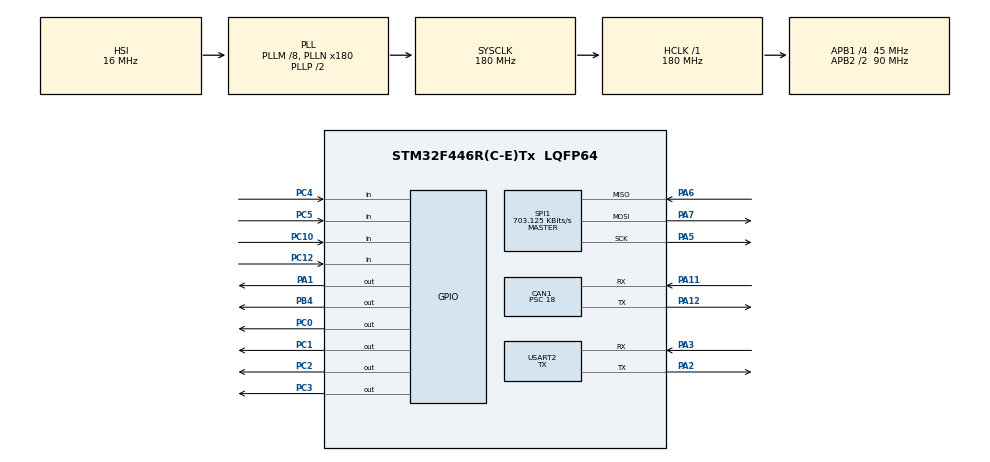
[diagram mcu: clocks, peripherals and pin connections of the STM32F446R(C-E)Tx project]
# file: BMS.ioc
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CAN1.BS1=CAN_BS1_3TQ
CAN1.CalculateBaudRate=500000
CAN1.CalculateTimeBit=2000
CAN1.CalculateTimeQuantum=400.0
CAN1.Prescaler=18
FREERTOS.Mutexes01=FEB_SM_Lock,Dynamic,NULL;FEB_LTC6811_Lock,Dynamic,NULL;FEB_UART_Lock,Dynamic,NULL
FREERTOS.Tasks01=Task1_VT,24,512,Start_Task1_VT,Default,NULL,Dynamic,NULL,NULL;Task2_State,32,256,Start_Task2_State,Default,NULL,Dynamic,NULL,NULL;Task3_Charge,40,256,Start_Task3_Charge,Default,NULL,Dynamic,NULL,NULL;Task4_Balance,33,512,Start_Task4_Balance,Default,NULL,Dynamic,NULL,NULL;Task5_IVT,25,512,Start_Task5_IVT,Default,NULL,Dynamic,NULL,NULL;Task6_CAN,16,128,Start_Task6_CAN,Default,NULL,Dynamic,NULL,NULL
FREERTOS.configUSE_NEWLIB_REENTRANT=1
Mcu.Family=STM32F4
Mcu.Name=STM32F446R(C-E)Tx
Mcu.Package=LQFP64
NVIC.CAN1_RX0_IRQn=true\:5\:0\:false\:false\:true\:true\:true\:true\:true
NVIC.PriorityGroup=NVIC_PRIORITYGROUP_4
NVIC.USART2_IRQn=true\:5\:0\:false\:false\:true\:true\:true\:true\:true
PA1.Signal=GPIO_Output
PA11.Mode=CAN_Activate
PA11.Signal=CAN1_RX
PA12.Mode=CAN_Activate
PA12.Signal=CAN1_TX
PA2.Mode=Asynchronous
PA2.Signal=USART2_TX
PA3.Mode=Asynchronous
PA3.Signal=USART2_RX
PA5.Mode=Full_Duplex_Master
PA5.Signal=SPI1_SCK
PA6.Mode=Full_Duplex_Master
PA6.Signal=SPI1_MISO
PA7.Mode=Full_Duplex_Master
PA7.Signal=SPI1_MOSI
PB4.Signal=GPIO_Output
PC0.Signal=GPIO_Output
PC1.Signal=GPIO_Output
PC10.Signal=GPIO_Input
PC12.Signal=GPIO_Input
PC2.Signal=GPIO_Output
PC3.Signal=GPIO_Output
PC4.Signal=GPIO_Input
PC5.Signal=GPIO_Input
ProjectManager.HeapSize=0x200
ProjectManager.StackSize=0x400
ProjectManager.TargetToolchain=STM32CubeIDE
RCC.AHBFreq_Value=180000000
RCC.APB1CLKDivider=RCC_HCLK_DIV4
RCC.APB1Freq_Value=45000000
RCC.APB1TimFreq_Value=90000000
RCC.APB2CLKDivider=RCC_HCLK_DIV2
RCC.APB2Freq_Value=90000000
RCC.APB2TimFreq_Value=180000000
RCC.CortexFreq_Value=180000000
RCC.HCLKFreq_Value=180000000
RCC.PLLM=8
RCC.PLLN=180
RCC.SYSCLKFreq_VALUE=180000000
RCC.SYSCLKSource=RCC_SYSCLKSOURCE_PLLCLK
RCC.USBFreq_Value=180000000
RCC.VCOOutputFreq_Value=360000000
SPI1.BaudRatePrescaler=SPI_BAUDRATEPRESCALER_128
SPI1.CalculateBaudRate=703.125 KBits/s
SPI1.Direction=SPI_DIRECTION_2LINES
SPI1.Mode=SPI_MODE_MASTER
SPI1.VirtualType=VM_MASTER
TIM4.Prescaler=63
USART2.Mode=MODE_TX
USART2.Parity=PARITY_EVEN
USART2.VirtualMode=VM_ASYNC
VP_FREERTOS_VS_CMSIS_V2.Mode=CMSIS_V2
VP_TIM4_VS_ClockSourceINT.Mode=Internal
board=custom

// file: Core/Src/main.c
/* USER CODE BEGIN Header */
/**
  ******************************************************************************
  * @file           : main.c
  * @brief          : Main program body
  ******************************************************************************
  * @attention
  *
  * Copyright (c) 2023 STMicroelectronics.
  * All rights reserved.
  *
  * This software is licensed under terms that can be found in the LICENSE file
  * in the root directory of this software component.
  * If no LICENSE file comes with this software, it is provided AS-IS.
  *
  ******************************************************************************
  */
/* USER CODE END Header */
#include "main.h"
#include "cmsis_os.h"

CAN_HandleTypeDef hcan1;

SPI_HandleTypeDef hspi1;

TIM_HandleTypeDef htim4;

UART_HandleTypeDef huart2;

/* Definitions for Task1_VT */
osThreadId_t Task1_VTHandle;
const osThreadAttr_t Task1_VT_attributes = {
  .name = "Task1_VT",
  .stack_size = 512 * 4,
  .priority = (osPriority_t) osPriorityNormal,
};
/* Definitions for Task2_State */
osThreadId_t Task2_StateHandle;
const osThreadAttr_t Task2_State_attributes = {
  .name = "Task2_State",
  .stack_size = 256 * 4,
  .priority = (osPriority_t) osPriorityAboveNormal,
};
/* Definitions for Task3_Charge */
osThreadId_t Task3_ChargeHandle;
const osThreadAttr_t Task3_Charge_attributes = {
  .name = "Task3_Charge",
  .stack_size = 256 * 4,
  .priority = (osPriority_t) osPriorityHigh,
};
/* Definitions for Task4_Balance */
osThreadId_t Task4_BalanceHandle;
const osThreadAttr_t Task4_Balance_attributes = {
  .name = "Task4_Balance",
  .stack_size = 512 * 4,
  .priority = (osPriority_t) osPriorityAboveNormal1,
};
/* Definitions for Task5_IVT */
osThreadId_t Task5_IVTHandle;
const osThreadAttr_t Task5_IVT_attributes = {
  .name = "Task5_IVT",
  .stack_size = 512 * 4,
  .priority = (osPriority_t) osPriorityNormal1,
};
/* Definitions for Task6_CAN */
osThreadId_t Task6_CANHandle;
const osThreadAttr_t Task6_CAN_attributes = {
  .name = "Task6_CAN",
  .stack_size = 128 * 4,
  .priority = (osPriority_t) osPriorityBelowNormal,
};
/* Definitions for FEB_SM_Lock */
osMutexId_t FEB_SM_LockHandle;
const osMutexAttr_t FEB_SM_Lock_attributes = {
  .name = "FEB_SM_Lock"
};
/* Definitions for FEB_LTC6811_Lock */
osMutexId_t FEB_LTC6811_LockHandle;
const osMutexAttr_t FEB_LTC6811_Lock_attributes = {
  .name = "FEB_LTC6811_Lock"
};
/* Definitions for FEB_UART_Lock */
osMutexId_t FEB_UART_LockHandle;
const osMutexAttr_t FEB_UART_Lock_attributes = {
  .name = "FEB_UART_Lock"
};

void SystemClock_Config(void);
static void MX_GPIO_Init(void);
static void MX_USART2_UART_Init(void);
static void MX_CAN1_Init(void);
static void MX_TIM4_Init(void);
static void MX_SPI1_Init(void);
void Start_Task1_VT(void *argument);
void Start_Task2_State(void *argument);
void Start_Task3_Charge(void *argument);
void Start_Task4_Balance(void *argument);
void Start_Task5_IVT(void *argument);
void Start_Task6_CAN(void *argument);

int main(void)
{

  /* MCU Configuration--------------------------------------------------------*/

  /* Reset of all peripherals, Initializes the Flash interface and the Systick. */
  HAL_Init();

  /* Configure the system clock */
  SystemClock_Config();

  /* Initialize all configured peripherals */
  MX_GPIO_Init();
  MX_USART2_UART_Init();
  MX_CAN1_Init();
  MX_TIM4_Init();
  MX_SPI1_Init();
  /* USER CODE BEGIN 2 */

  FEB_Main_Setup();

  /* USER CODE END 2 */

  /* Init scheduler */
  osKernelInitialize();
  /* Create the mutex(es) */
  /* creation of FEB_SM_Lock */
  FEB_SM_LockHandle = osMutexNew(&FEB_SM_Lock_attributes);

  /* creation of FEB_LTC6811_Lock */
  FEB_LTC6811_LockHandle = osMutexNew(&FEB_LTC6811_Lock_attributes);

  /* creation of FEB_UART_Lock */
  FEB_UART_LockHandle = osMutexNew(&FEB_UART_Lock_attributes);

  /* Create the thread(s) */
  /* creation of Task1_VT */
  Task1_VTHandle = osThreadNew(Start_Task1_VT, NULL, &Task1_VT_attributes);

  /* creation of Task2_State */
  Task2_StateHandle = osThreadNew(Start_Task2_State, NULL, &Task2_State_attributes);

  /* creation of Task3_Charge */
  Task3_ChargeHandle = osThreadNew(Start_Task3_Charge, NULL, &Task3_Charge_attributes);

  /* creation of Task4_Balance */
  Task4_BalanceHandle = osThreadNew(Start_Task4_Balance, NULL, &Task4_Balance_attributes);

  /* creation of Task5_IVT */
  Task5_IVTHandle = osThreadNew(Start_Task5_IVT, NULL, &Task5_IVT_attributes);

  /* creation of Task6_CAN */
  Task6_CANHandle = osThreadNew(Start_Task6_CAN, NULL, &Task6_CAN_attributes);

  /* Start scheduler */
  osKernelStart();

  /* We should never get here as control is now taken by the scheduler */

  /* Infinite loop */
  while (1)
  {

  }
}

void SystemClock_Config(void)
{
  RCC_OscInitTypeDef RCC_OscInitStruct = {0};
  RCC_ClkInitTypeDef RCC_ClkInitStruct = {0};

  /** Configure the main internal regulator output voltage
  */
  __HAL_RCC_PWR_CLK_ENABLE();
  __HAL_PWR_VOLTAGESCALING_CONFIG(PWR_REGULATOR_VOLTAGE_SCALE1);

  /** Initializes the RCC Oscillators according to the specified parameters
  * in the RCC_OscInitTypeDef structure.
  */
  RCC_OscInitStruct.OscillatorType = RCC_OSCILLATORTYPE_HSI;
  RCC_OscInitStruct.HSIState = RCC_HSI_ON;
  RCC_OscInitStruct.HSICalibrationValue = RCC_HSICALIBRATION_DEFAULT;
  RCC_OscInitStruct.PLL.PLLState = RCC_PLL_ON;
  RCC_OscInitStruct.PLL.PLLSource = RCC_PLLSOURCE_HSI;
  RCC_OscInitStruct.PLL.PLLM = 8;
  RCC_OscInitStruct.PLL.PLLN = 180;
  RCC_OscInitStruct.PLL.PLLP = RCC_PLLP_DIV2;
  RCC_OscInitStruct.PLL.PLLQ = 2;
  RCC_OscInitStruct.PLL.PLLR = 2;
  if (HAL_RCC_OscConfig(&RCC_OscInitStruct) != HAL_OK)
  {
    Error_Handler();
  }

  /** Activate the Over-Drive mode
  */
  if (HAL_PWREx_EnableOverDrive() != HAL_OK)
  {
    Error_Handler();
  }

  /** Initializes the CPU, AHB and APB buses clocks
  */
  RCC_ClkInitStruct.ClockType = RCC_CLOCKTYPE_HCLK|RCC_CLOCKTYPE_SYSCLK
                              |RCC_CLOCKTYPE_PCLK1|RCC_CLOCKTYPE_PCLK2;
  RCC_ClkInitStruct.SYSCLKSource = RCC_SYSCLKSOURCE_PLLCLK;
  RCC_ClkInitStruct.AHBCLKDivider = RCC_SYSCLK_DIV1;
  RCC_ClkInitStruct.APB1CLKDivider = RCC_HCLK_DIV4;
  RCC_ClkInitStruct.APB2CLKDivider = RCC_HCLK_DIV2;

  if (HAL_RCC_ClockConfig(&RCC_ClkInitStruct, FLASH_LATENCY_5) != HAL_OK)
  {
    Error_Handler();
  }
}

static void MX_CAN1_Init(void)
{

  hcan1.Instance = CAN1;
  hcan1.Init.Prescaler = 18;
  hcan1.Init.Mode = CAN_MODE_NORMAL;
  hcan1.Init.SyncJumpWidth = CAN_SJW_1TQ;
  hcan1.Init.TimeSeg1 = CAN_BS1_3TQ;
  hcan1.Init.TimeSeg2 = CAN_BS2_1TQ;
  hcan1.Init.TimeTriggeredMode = DISABLE;
  hcan1.Init.AutoBusOff = DISABLE;
  hcan1.Init.AutoWakeUp = DISABLE;
  hcan1.Init.AutoRetransmission = DISABLE;
  hcan1.Init.ReceiveFifoLocked = DISABLE;
  hcan1.Init.TransmitFifoPriority = DISABLE;
  if (HAL_CAN_Init(&hcan1) != HAL_OK)
  {
    Error_Handler();
  }

}

static void MX_SPI1_Init(void)
{

  /* SPI1 parameter configuration*/
  hspi1.Instance = SPI1;
  hspi1.Init.Mode = SPI_MODE_MASTER;
  hspi1.Init.Direction = SPI_DIRECTION_2LINES;
  hspi1.Init.DataSize = SPI_DATASIZE_8BIT;
  hspi1.Init.CLKPolarity = SPI_POLARITY_LOW;
  hspi1.Init.CLKPhase = SPI_PHASE_1EDGE;
  hspi1.Init.NSS = SPI_NSS_SOFT;
  hspi1.Init.BaudRatePrescaler = SPI_BAUDRATEPRESCALER_128;
  hspi1.Init.FirstBit = SPI_FIRSTBIT_MSB;
  hspi1.Init.TIMode = SPI_TIMODE_DISABLE;
  hspi1.Init.CRCCalculation = SPI_CRCCALCULATION_DISABLE;
  hspi1.Init.CRCPolynomial = 10;
  if (HAL_SPI_Init(&hspi1) != HAL_OK)
  {
    Error_Handler();
  }

}

static void MX_TIM4_Init(void)
{

  TIM_ClockConfigTypeDef sClockSourceConfig = {0};
  TIM_MasterConfigTypeDef sMasterConfig = {0};

  htim4.Instance = TIM4;
  htim4.Init.Prescaler = 63;
  htim4.Init.CounterMode = TIM_COUNTERMODE_UP;
  htim4.Init.Period = 65535;
  htim4.Init.ClockDivision = TIM_CLOCKDIVISION_DIV1;
  htim4.Init.AutoReloadPreload = TIM_AUTORELOAD_PRELOAD_DISABLE;
  if (HAL_TIM_Base_Init(&htim4) != HAL_OK)
  {
    Error_Handler();
  }
  sClockSourceConfig.ClockSource = TIM_CLOCKSOURCE_INTERNAL;
  if (HAL_TIM_ConfigClockSource(&htim4, &sClockSourceConfig) != HAL_OK)
  {
    Error_Handler();
  }
  sMasterConfig.MasterOutputTrigger = TIM_TRGO_RESET;
  sMasterConfig.MasterSlaveMode = TIM_MASTERSLAVEMODE_DISABLE;
  if (HAL_TIMEx_MasterConfigSynchronization(&htim4, &sMasterConfig) != HAL_OK)
  {
    Error_Handler();
  }

}

static void MX_USART2_UART_Init(void)
{

  huart2.Instance = USART2;
  huart2.Init.BaudRate = 115200;
  huart2.Init.WordLength = UART_WORDLENGTH_8B;
  huart2.Init.StopBits = UART_STOPBITS_1;
  huart2.Init.Parity = UART_PARITY_EVEN;
  huart2.Init.Mode = UART_MODE_TX;
  huart2.Init.HwFlowCtl = UART_HWCONTROL_NONE;
  huart2.Init.OverSampling = UART_OVERSAMPLING_16;
  if (HAL_UART_Init(&huart2) != HAL_OK)
  {
    Error_Handler();
  }

}

static void MX_GPIO_Init(void)
{
  GPIO_InitTypeDef GPIO_InitStruct = {0};

  /* GPIO Ports Clock Enable */
  __HAL_RCC_GPIOC_CLK_ENABLE();
  __HAL_RCC_GPIOA_CLK_ENABLE();
  __HAL_RCC_GPIOB_CLK_ENABLE();

  /*Configure GPIO pin Output Level */
  HAL_GPIO_WritePin(GPIOC, GPIO_PIN_0|GPIO_PIN_1|GPIO_PIN_2|GPIO_PIN_3, GPIO_PIN_RESET);

  /*Configure GPIO pin Output Level */
  HAL_GPIO_WritePin(GPIOA, GPIO_PIN_1, GPIO_PIN_RESET);

  /*Configure GPIO pin Output Level */
  HAL_GPIO_WritePin(GPIOB, GPIO_PIN_4, GPIO_PIN_RESET);

  /*Configure GPIO pins : PC0 PC1 PC2 PC3 */
  GPIO_InitStruct.Pin = GPIO_PIN_0|GPIO_PIN_1|GPIO_PIN_2|GPIO_PIN_3;
  GPIO_InitStruct.Mode = GPIO_MODE_OUTPUT_PP;
  GPIO_InitStruct.Pull = GPIO_NOPULL;
  GPIO_InitStruct.Speed = GPIO_SPEED_FREQ_LOW;
  HAL_GPIO_Init(GPIOC, &GPIO_InitStruct);

  /*Configure GPIO pin : PA1 */
  GPIO_InitStruct.Pin = GPIO_PIN_1;
  GPIO_InitStruct.Mode = GPIO_MODE_OUTPUT_PP;
  GPIO_InitStruct.Pull = GPIO_NOPULL;
  GPIO_InitStruct.Speed = GPIO_SPEED_FREQ_LOW;
  HAL_GPIO_Init(GPIOA, &GPIO_InitStruct);

  /*Configure GPIO pins : PC4 PC5 PC10 PC12 */
  GPIO_InitStruct.Pin = GPIO_PIN_4|GPIO_PIN_5|GPIO_PIN_10|GPIO_PIN_12;
  GPIO_InitStruct.Mode = GPIO_MODE_INPUT;
  GPIO_InitStruct.Pull = GPIO_NOPULL;
  HAL_GPIO_Init(GPIOC, &GPIO_InitStruct);

  /*Configure GPIO pin : PB4 */
  GPIO_InitStruct.Pin = GPIO_PIN_4;
  GPIO_InitStruct.Mode = GPIO_MODE_OUTPUT_PP;
  GPIO_InitStruct.Pull = GPIO_NOPULL;
  GPIO_InitStruct.Speed = GPIO_SPEED_FREQ_LOW;
  HAL_GPIO_Init(GPIOB, &GPIO_InitStruct);

}

void Start_Task1_VT(void *argument)
{
  /* USER CODE BEGIN 5 */
  /* Infinite loop */
  FEB_Task_ADBMS();
  /* USER CODE END 5 */
}

void Start_Task2_State(void *argument)
{
  /* USER CODE BEGIN Start_Task2_State */
  /* Infinite loop */
  FEB_Main_Task2_State();
  /* USER CODE END Start_Task2_State */
}

void Start_Task3_Charge(void *argument)
{
  /* USER CODE BEGIN Start_Task3_Charge */
  /* Infinite loop */
  FEB_Task_Charge();
  /* USER CODE END Start_Task3_Charge */
}

void Start_Task4_Balance(void *argument)
{
  /* USER CODE BEGIN Start_Task4_Balance */
  /* Infinite loop */
  FEB_Task_Balance();
  /* USER CODE END Start_Task4_Balance */
}

void Start_Task5_IVT(void *argument)
{
  /* USER CODE BEGIN Start_Task5_IVT */
  /* Infinite loop */
  FEB_Task_IVT();
  /* USER CODE END Start_Task5_IVT */
}

void Start_Task6_CAN(void *argument)
{
  /* USER CODE BEGIN Start_Task6_CAN */
  /* Infinite loop */
  FEB_Task_CAN();
  /* USER CODE END Start_Task6_CAN */
}

void Error_Handler(void)
{
  __disable_irq();
  while (1)
  {
  }
}
